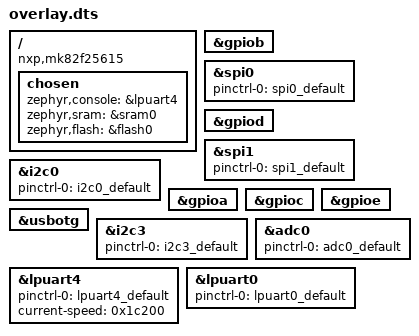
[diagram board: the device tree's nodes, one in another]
/ {
	compatible = "nxp,mk82f25615", "nxp,k82f", "nxp,k8x";
	chosen {
		zephyr,console = &lpuart4;
		zephyr,sram = &sram0;
		zephyr,flash = &flash0;
	};
};
&gpiob{
	status = "okay";
};
&spi0{
	status = "okay";
	pinctrl-0 = < &spi0_default >;
	pinctrl-names = "default";
};
&gpiod{
	status = "okay";
};
&spi1{
	status = "okay";
	pinctrl-0 = < &spi1_default >;
	pinctrl-names = "default";
};
&i2c0{
	status = "okay";
	pinctrl-0 = < &i2c0_default >;
	pinctrl-names = "default";
};
&gpioa{
	status = "okay";
};
&gpioc{
	status = "okay";
};
&gpioe{
	status = "okay";
};
&usbotg{
	status = "okay";
};
&i2c3{
	status = "okay";
	pinctrl-0 = < &i2c3_default >;
	pinctrl-names = "default";
};
&lpuart4{
	status = "okay";
	pinctrl-0 = < &lpuart4_default >;
	pinctrl-names = "default";
	current-speed = < 0x1c200 >;
};
&adc0{
	status = "okay";
	pinctrl-0 = < &adc0_default >;
	pinctrl-names = "default";
};
&lpuart0{
	pinctrl-0 = < &lpuart0_default >;
	pinctrl-names = "default";
};
